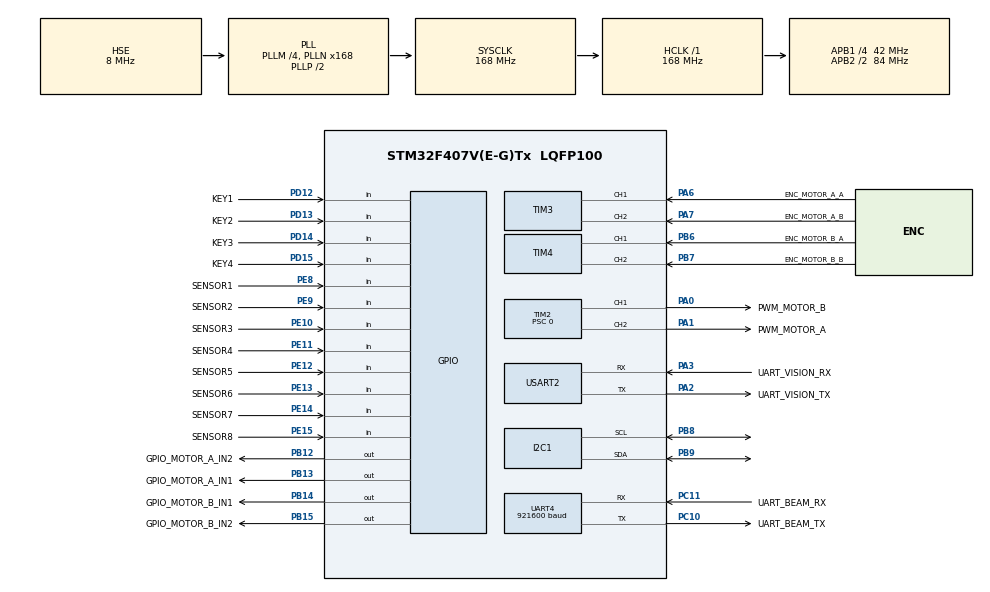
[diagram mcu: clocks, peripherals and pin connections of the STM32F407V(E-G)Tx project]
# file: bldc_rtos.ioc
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FREERTOS.Tasks01=defaultTask,24,128,StartDefaultTask,Default,NULL,Dynamic,NULL,NULL
Mcu.Family=STM32F4
Mcu.Name=STM32F407V(E-G)Tx
Mcu.Package=LQFP100
NVIC.PriorityGroup=NVIC_PRIORITYGROUP_4
NVIC.TIM1_UP_TIM10_IRQn=true\:15\:0\:false\:false\:true\:false\:false\:true\:true
NVIC.TIM5_IRQn=true\:5\:0\:false\:false\:true\:true\:true\:true\:true
NVIC.TimeBase=TIM1_UP_TIM10_IRQn
NVIC.TimeBaseIP=TIM1
NVIC.UART4_IRQn=true\:5\:0\:false\:false\:true\:true\:true\:true\:true
NVIC.USART2_IRQn=true\:5\:0\:false\:false\:true\:true\:true\:true\:true
PA0-WKUP.Signal=S_TIM2_CH1_ETR
PA1.Signal=S_TIM2_CH2
PA13.Mode=Serial_Wire
PA13.Signal=SYS_JTMS-SWDIO
PA14.Mode=Serial_Wire
PA14.Signal=SYS_JTCK-SWCLK
PA2.Mode=Asynchronous
PA2.Signal=USART2_TX
PA3.Mode=Asynchronous
PA3.Signal=USART2_RX
PA6.Signal=S_TIM3_CH1
PA7.Signal=S_TIM3_CH2
PB12.Signal=GPIO_Output
PB13.Signal=GPIO_Output
PB14.Signal=GPIO_Output
PB15.Signal=GPIO_Output
PB6.Signal=S_TIM4_CH1
PB7.Signal=S_TIM4_CH2
PB8.Mode=I2C
PB8.Signal=I2C1_SCL
PB9.Mode=I2C
PB9.Signal=I2C1_SDA
PC10.Mode=Asynchronous
PC10.Signal=UART4_TX
PC11.Mode=Asynchronous
PC11.Signal=UART4_RX
PD12.GPIO_Label=KEY1
PD12.GPIO_PuPd=GPIO_PULLUP
PD12.Signal=GPIO_Input
PD13.GPIO_Label=KEY2
PD13.GPIO_PuPd=GPIO_PULLUP
PD13.Signal=GPIO_Input
PD14.GPIO_Label=KEY3
PD14.GPIO_PuPd=GPIO_PULLUP
PD14.Signal=GPIO_Input
PD15.GPIO_Label=KEY4
PD15.GPIO_PuPd=GPIO_PULLUP
PD15.Signal=GPIO_Input
PE10.GPIO_Label=SENSOR3
PE10.Signal=GPIO_Input
PE11.GPIO_Label=SENSOR4
PE11.Signal=GPIO_Input
PE12.GPIO_Label=SENSOR5
PE12.Signal=GPIO_Input
PE13.GPIO_Label=SENSOR6
PE13.Signal=GPIO_Input
PE14.GPIO_Label=SENSOR7
PE14.Signal=GPIO_Input
PE15.GPIO_Label=SENSOR8
PE15.Signal=GPIO_Input
PE8.GPIO_Label=SENSOR1
PE8.Signal=GPIO_Input
PE9.GPIO_Label=SENSOR2
PE9.Signal=GPIO_Input
PH0-OSC_IN.Mode=HSE-External-Oscillator
PH0-OSC_IN.Signal=RCC_OSC_IN
PH1-OSC_OUT.Mode=HSE-External-Oscillator
PH1-OSC_OUT.Signal=RCC_OSC_OUT
ProjectManager.HeapSize=0x200
ProjectManager.StackSize=0x400
ProjectManager.TargetToolchain=MDK-ARM V5.32
RCC.48MHZClocksFreq_Value=84000000
RCC.AHBFreq_Value=168000000
RCC.APB1CLKDivider=RCC_HCLK_DIV4
RCC.APB1Freq_Value=42000000
RCC.APB1TimFreq_Value=84000000
RCC.APB2CLKDivider=RCC_HCLK_DIV2
RCC.APB2Freq_Value=84000000
RCC.APB2TimFreq_Value=168000000
RCC.CortexFreq_Value=168000000
RCC.HCLKFreq_Value=168000000
RCC.HSE_VALUE=8000000
RCC.HSI_VALUE=16000000
RCC.LSE_VALUE=32768
RCC.PLLM=4
RCC.PLLN=168
RCC.PLLSourceVirtual=RCC_PLLSOURCE_HSE
RCC.SYSCLKFreq_VALUE=168000000
RCC.SYSCLKSource=RCC_SYSCLKSOURCE_PLLCLK
RCC.VCOOutputFreq_Value=336000000
SH.S_TIM2_CH1_ETR.0=TIM2_CH1,PWM Generation1 CH1
SH.S_TIM2_CH2.0=TIM2_CH2,PWM Generation2 CH2
SH.S_TIM3_CH1.0=TIM3_CH1,Encoder_Interface
SH.S_TIM3_CH2.0=TIM3_CH2,Encoder_Interface
SH.S_TIM4_CH1.0=TIM4_CH1,Encoder_Interface
SH.S_TIM4_CH2.0=TIM4_CH2,Encoder_Interface
TIM2.Channel-PWM\ Generation1\ CH1=TIM_CHANNEL_1
TIM2.Channel-PWM\ Generation2\ CH2=TIM_CHANNEL_2
TIM2.Period=4200-1
TIM2.Prescaler=0
TIM3.EncoderMode=TIM_ENCODERMODE_TI12
TIM4.EncoderMode=TIM_ENCODERMODE_TI12
TIM5.Period=1000-1
TIM5.Prescaler=168-1
UART4.BaudRate=921600
UART4.VirtualMode=Asynchronous
USART2.VirtualMode=VM_ASYNC
VP_FREERTOS_VS_CMSIS_V2.Mode=CMSIS_V2
VP_SYS_VS_tim1.Mode=TIM1
VP_TIM2_VS_ClockSourceINT.Mode=Internal
VP_TIM5_VS_ClockSourceINT.Mode=Internal
board=custom
PB13.GPIO_Label=GPIO_MOTOR_A_IN1
PB12.GPIO_Label=GPIO_MOTOR_A_IN2
PB14.GPIO_Label=GPIO_MOTOR_B_IN1
PB15.GPIO_Label=GPIO_MOTOR_B_IN2
PA1.GPIO_Label=PWM_MOTOR_A
PA0-WKUP.GPIO_Label=PWM_MOTOR_B
PA6.GPIO_Label=ENC_MOTOR_A_A
PA7.GPIO_Label=ENC_MOTOR_A_B
PB6.GPIO_Label=ENC_MOTOR_B_A
PB7.GPIO_Label=ENC_MOTOR_B_B
PC10.GPIO_Label=UART_BEAM_TX
PC11.GPIO_Label=UART_BEAM_RX
PA2.GPIO_Label=UART_VISION_TX
PA3.GPIO_Label=UART_VISION_RX

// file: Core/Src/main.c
/* USER CODE BEGIN Header */
/**
 * 【合成样例】按 STM32CubeMX 6.x（STM32CubeF4 + FreeRTOS CMSIS_V2）生成代码的结构手写，用于验证
 * ports/stm32-cubemx 的 FreeRTOS / TIM 时基模式。**不是 CubeMX 的真实输出，未上板测试。**
 * 与框架的接缝：USER CODE Includes / 2 / 5（默认任务循环）/ Callback 1（TIM 回调转发）。
 */
/* USER CODE END Header */
#include "main.h"
#include "cmsis_os.h"

/* USER CODE BEGIN Includes */
#include "dz_cubemx.h"
/* USER CODE END Includes */

I2C_HandleTypeDef hi2c1;
TIM_HandleTypeDef htim2;
TIM_HandleTypeDef htim3;
TIM_HandleTypeDef htim4;
TIM_HandleTypeDef htim5;
UART_HandleTypeDef huart4;
UART_HandleTypeDef huart2;

osThreadId_t defaultTaskHandle;
const osThreadAttr_t defaultTask_attributes = {
  .name = "defaultTask",
  .stack_size = 128 * 4,
  .priority = (osPriority_t) osPriorityNormal,
};

void SystemClock_Config(void);
static void MX_GPIO_Init(void);
static void MX_TIM2_Init(void);
static void MX_TIM3_Init(void);
static void MX_TIM4_Init(void);
static void MX_I2C1_Init(void);
static void MX_TIM5_Init(void);
static void MX_UART4_Init(void);
static void MX_USART2_UART_Init(void);
void StartDefaultTask(void *argument);
void HAL_TIM_MspPostInit(TIM_HandleTypeDef *htim);

int main(void)
{
  HAL_Init();
  SystemClock_Config();
  MX_GPIO_Init();
  MX_TIM2_Init();
  MX_TIM3_Init();
  MX_TIM4_Init();
  MX_I2C1_Init();
  MX_TIM5_Init();
  MX_UART4_Init();
  MX_USART2_UART_Init();
  /* USER CODE BEGIN 2 */
  dz_cubemx_start();
  /* USER CODE END 2 */
  osKernelInitialize();
  defaultTaskHandle = osThreadNew(StartDefaultTask, NULL, &defaultTask_attributes);
  osKernelStart();
  while (1)
  {
  }
}

void SystemClock_Config(void)
{
  RCC_OscInitTypeDef RCC_OscInitStruct = {0};
  RCC_ClkInitTypeDef RCC_ClkInitStruct = {0};
  __HAL_RCC_PWR_CLK_ENABLE();
  __HAL_PWR_VOLTAGESCALING_CONFIG(PWR_REGULATOR_VOLTAGE_SCALE1);
  RCC_OscInitStruct.OscillatorType = RCC_OSCILLATORTYPE_HSE;
  RCC_OscInitStruct.HSEState = RCC_HSE_ON;
  RCC_OscInitStruct.PLL.PLLState = RCC_PLL_ON;
  RCC_OscInitStruct.PLL.PLLSource = RCC_PLLSOURCE_HSE;
  RCC_OscInitStruct.PLL.PLLM = 4;
  RCC_OscInitStruct.PLL.PLLN = 168;
  RCC_OscInitStruct.PLL.PLLP = RCC_PLLP_DIV2;
  RCC_OscInitStruct.PLL.PLLQ = 4;
  if (HAL_RCC_OscConfig(&RCC_OscInitStruct) != HAL_OK) Error_Handler();
  RCC_ClkInitStruct.ClockType = RCC_CLOCKTYPE_HCLK|RCC_CLOCKTYPE_SYSCLK|RCC_CLOCKTYPE_PCLK1|RCC_CLOCKTYPE_PCLK2;
  RCC_ClkInitStruct.SYSCLKSource = RCC_SYSCLKSOURCE_PLLCLK;
  RCC_ClkInitStruct.AHBCLKDivider = RCC_SYSCLK_DIV1;
  RCC_ClkInitStruct.APB1CLKDivider = RCC_HCLK_DIV4;
  RCC_ClkInitStruct.APB2CLKDivider = RCC_HCLK_DIV2;
  if (HAL_RCC_ClockConfig(&RCC_ClkInitStruct, FLASH_LATENCY_5) != HAL_OK) Error_Handler();
}

static void MX_I2C1_Init(void)
{
  hi2c1.Instance = I2C1;
  hi2c1.Init.ClockSpeed = 100000;
  hi2c1.Init.DutyCycle = I2C_DUTYCYCLE_2;
  hi2c1.Init.OwnAddress1 = 0;
  hi2c1.Init.AddressingMode = I2C_ADDRESSINGMODE_7BIT;
  hi2c1.Init.DualAddressMode = I2C_DUALADDRESS_DISABLE;
  hi2c1.Init.OwnAddress2 = 0;
  hi2c1.Init.GeneralCallMode = I2C_GENERALCALL_DISABLE;
  hi2c1.Init.NoStretchMode = I2C_NOSTRETCH_DISABLE;
  if (HAL_I2C_Init(&hi2c1) != HAL_OK) Error_Handler();
}

static void MX_TIM2_Init(void)
{
  TIM_OC_InitTypeDef sConfigOC = {0};
  htim2.Instance = TIM2;
  htim2.Init.Prescaler = 0;           /* 84MHz/1/4200 = 20 kHz（原工程 500 Hz） */
  htim2.Init.CounterMode = TIM_COUNTERMODE_UP;
  htim2.Init.Period = 4200-1;
  htim2.Init.ClockDivision = TIM_CLOCKDIVISION_DIV1;
  htim2.Init.AutoReloadPreload = TIM_AUTORELOAD_PRELOAD_DISABLE;
  if (HAL_TIM_PWM_Init(&htim2) != HAL_OK) Error_Handler();
  sConfigOC.OCMode = TIM_OCMODE_PWM1;
  sConfigOC.Pulse = 0;
  sConfigOC.OCPolarity = TIM_OCPOLARITY_HIGH;
  sConfigOC.OCFastMode = TIM_OCFAST_DISABLE;
  if (HAL_TIM_PWM_ConfigChannel(&htim2, &sConfigOC, TIM_CHANNEL_1) != HAL_OK) Error_Handler();
  if (HAL_TIM_PWM_ConfigChannel(&htim2, &sConfigOC, TIM_CHANNEL_2) != HAL_OK) Error_Handler();
  HAL_TIM_MspPostInit(&htim2);
}

static void enc_init(TIM_HandleTypeDef *h, TIM_TypeDef *inst)
{
  /* 注：CubeMX 实际会把每个 MX_TIMx_Init 展开写；此处合并只为样例简短，生成效果相同。 */
  TIM_Encoder_InitTypeDef sConfig = {0};
  h->Instance = inst;
  h->Init.Prescaler = 0;
  h->Init.CounterMode = TIM_COUNTERMODE_UP;
  h->Init.Period = 65535;
  h->Init.ClockDivision = TIM_CLOCKDIVISION_DIV1;
  h->Init.AutoReloadPreload = TIM_AUTORELOAD_PRELOAD_DISABLE;
  sConfig.EncoderMode = TIM_ENCODERMODE_TI12;
  sConfig.IC1Polarity = TIM_ICPOLARITY_RISING; sConfig.IC1Selection = TIM_ICSELECTION_DIRECTTI;
  sConfig.IC1Prescaler = TIM_ICPSC_DIV1; sConfig.IC1Filter = 0;
  sConfig.IC2Polarity = TIM_ICPOLARITY_RISING; sConfig.IC2Selection = TIM_ICSELECTION_DIRECTTI;
  sConfig.IC2Prescaler = TIM_ICPSC_DIV1; sConfig.IC2Filter = 0;
  if (HAL_TIM_Encoder_Init(h, &sConfig) != HAL_OK) Error_Handler();
}
static void MX_TIM3_Init(void) { enc_init(&htim3, TIM3); }
static void MX_TIM4_Init(void) { enc_init(&htim4, TIM4); }

static void MX_TIM5_Init(void)
{
  htim5.Instance = TIM5;
  htim5.Init.Prescaler = 168-1;
  htim5.Init.CounterMode = TIM_COUNTERMODE_UP;
  htim5.Init.Period = 1000-1;
  htim5.Init.ClockDivision = TIM_CLOCKDIVISION_DIV1;
  htim5.Init.AutoReloadPreload = TIM_AUTORELOAD_PRELOAD_DISABLE;
  if (HAL_TIM_Base_Init(&htim5) != HAL_OK) Error_Handler();
}

static void uart_init(UART_HandleTypeDef *h, USART_TypeDef *inst, uint32_t baud)
{
  h->Instance = inst;
  h->Init.BaudRate = baud;
  h->Init.WordLength = UART_WORDLENGTH_8B;
  h->Init.StopBits = UART_STOPBITS_1;
  h->Init.Parity = UART_PARITY_NONE;
  h->Init.Mode = UART_MODE_TX_RX;
  h->Init.HwFlowCtl = UART_HWCONTROL_NONE;
  h->Init.OverSampling = UART_OVERSAMPLING_16;
  if (HAL_UART_Init(h) != HAL_OK) Error_Handler();
}
static void MX_UART4_Init(void) { uart_init(&huart4, UART4, 921600); }
static void MX_USART2_UART_Init(void) { uart_init(&huart2, USART2, 115200); }

static void MX_GPIO_Init(void)
{
  GPIO_InitTypeDef GPIO_InitStruct = {0};
  __HAL_RCC_GPIOE_CLK_ENABLE();
  __HAL_RCC_GPIOH_CLK_ENABLE();
  __HAL_RCC_GPIOA_CLK_ENABLE();
  __HAL_RCC_GPIOB_CLK_ENABLE();
  __HAL_RCC_GPIOD_CLK_ENABLE();
  __HAL_RCC_GPIOC_CLK_ENABLE();
  HAL_GPIO_WritePin(GPIOB, GPIO_MOTOR_A_IN2_Pin|GPIO_MOTOR_A_IN1_Pin|GPIO_MOTOR_B_IN1_Pin|GPIO_MOTOR_B_IN2_Pin, GPIO_PIN_RESET);
  GPIO_InitStruct.Pin = GPIO_PIN_8|GPIO_PIN_9|GPIO_PIN_10|GPIO_PIN_11|GPIO_PIN_12|GPIO_PIN_13|GPIO_PIN_14|GPIO_PIN_15;
  GPIO_InitStruct.Mode = GPIO_MODE_INPUT;
  GPIO_InitStruct.Pull = GPIO_NOPULL;
  HAL_GPIO_Init(GPIOE, &GPIO_InitStruct);
  GPIO_InitStruct.Pin = GPIO_PIN_12|GPIO_PIN_13|GPIO_PIN_14|GPIO_PIN_15;
  HAL_GPIO_Init(GPIOD, &GPIO_InitStruct);
  GPIO_InitStruct.Pin = GPIO_MOTOR_A_IN2_Pin|GPIO_MOTOR_A_IN1_Pin|GPIO_MOTOR_B_IN1_Pin|GPIO_MOTOR_B_IN2_Pin;
  GPIO_InitStruct.Mode = GPIO_MODE_OUTPUT_PP;
  GPIO_InitStruct.Speed = GPIO_SPEED_FREQ_LOW;
  HAL_GPIO_Init(GPIOB, &GPIO_InitStruct);
}

void StartDefaultTask(void *argument)
{
  /* USER CODE BEGIN 5 */
  (void)argument;
  for(;;)
  {
    dz_cubemx_loop();
    osDelay(1);
  }
  /* USER CODE END 5 */
}

void HAL_TIM_PeriodElapsedCallback(TIM_HandleTypeDef *htim)
{
  if (htim->Instance == TIM1) {
    HAL_IncTick();
  }
  /* USER CODE BEGIN Callback 1 */
  dz_cubemx_tim_callback(htim);
  /* USER CODE END Callback 1 */
}

void Error_Handler(void)
{
  __disable_irq();
  while (1) { }
}
